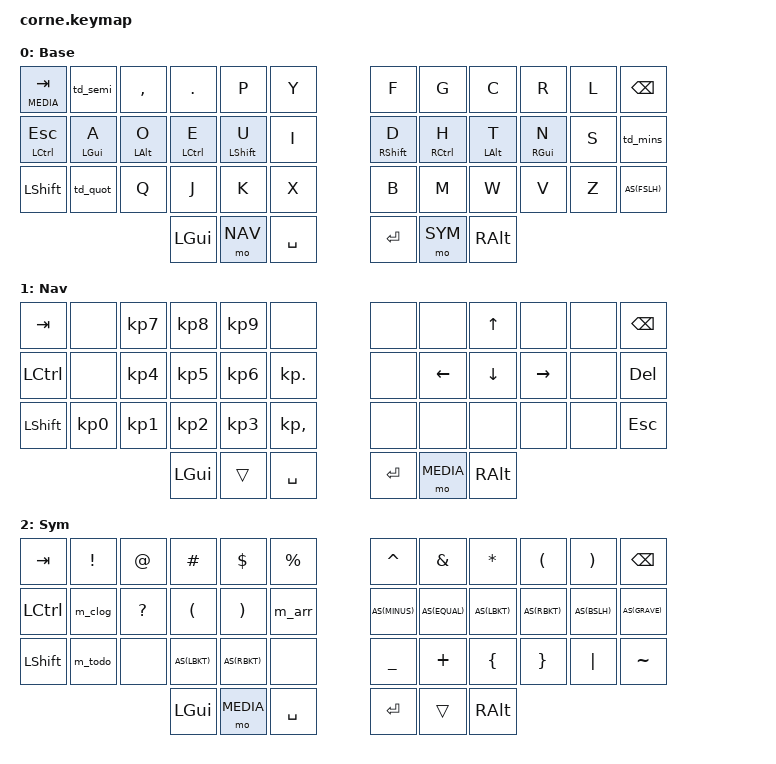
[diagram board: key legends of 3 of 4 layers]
// Port a ZMK de current/qmk/keymap.c. Mantener ambos sincronizados.

#include <behaviors.dtsi>
#include <dt-bindings/zmk/keys.h>
#include <dt-bindings/zmk/bt.h>
#include <dt-bindings/zmk/outputs.h>

#define BASE  0
#define NAV   1
#define SYM   2
#define MEDIA 3

// Auto Shift (QMK AUTO_SHIFT + NO_AUTO_SHIFT_ALPHA): tap = tecla, mantener
// 200 ms = tecla con Shift. Pulsar otra tecla antes resuelve como tap.
// Solo en números y símbolos sin Shift.
#define AS(k) &ashift LS(k) k

// ── Hold-tap global (equivale a TAPPING_TERM 220 + TAPPING_FORCE_HOLD, sin
// PERMISSIVE_HOLD): decide solo por tiempo, sin auto-repeat tras un tap ─────
&mt {
    flavor = "tap-preferred";
    tapping-term-ms = <220>;
    quick-tap-ms = <0>;
};

&lt {
    tapping-term-ms = <220>;
    quick-tap-ms = <0>;
};

/ {
    behaviors {
        ashift: auto_shift {
            compatible = "zmk,behavior-hold-tap";
            #binding-cells = <2>;
            flavor = "tap-unless-interrupted";
            tapping-term-ms = <200>;
            quick-tap-ms = <0>;
            bindings = <&kp>, <&kp>;
        };

        // ── Tap Dance ────────────────────────────────────────────────────
        td_semi: td_semi {
            compatible = "zmk,behavior-tap-dance";
            #binding-cells = <0>;
            tapping-term-ms = <220>;
            bindings = <&kp SEMI>, <&kp COLON>;
        };
        td_quot: td_quot {
            compatible = "zmk,behavior-tap-dance";
            #binding-cells = <0>;
            tapping-term-ms = <220>;
            bindings = <&kp SQT>, <&kp DQT>;
        };
        td_mins: td_mins {
            compatible = "zmk,behavior-tap-dance";
            #binding-cells = <0>;
            tapping-term-ms = <220>;
            bindings = <&kp MINUS>, <&kp UNDER>;
        };
    };

    // ── Macros ───────────────────────────────────────────────────────────
    macros {
        m_clog: m_clog {
            compatible = "zmk,behavior-macro";
            #binding-cells = <0>;
            bindings = <&macro_tap &kp C &kp O &kp N &kp S &kp O &kp L &kp E
                        &kp DOT &kp L &kp O &kp G &kp LPAR &kp RPAR>;
        };
        m_arr: m_arr {
            compatible = "zmk,behavior-macro";
            #binding-cells = <0>;
            bindings = <&macro_tap &kp LPAR &kp RPAR &kp SPACE &kp EQUAL &kp GT
                        &kp SPACE &kp LBRC &kp RBRC>;
        };
        m_todo: m_todo {
            compatible = "zmk,behavior-macro";
            #binding-cells = <0>;
            bindings = <&macro_tap &kp FSLH &kp FSLH &kp SPACE &kp T &kp O &kp D
                        &kp O &kp COLON &kp SPACE>;
        };
    };

    // ── Combos (posiciones: 0-11 fila 1, 12-23 fila 2, 24-35 fila 3,
    // 36-41 pulgares) ────────────────────────────────────────────────────
    combos {
        compatible = "zmk,combos";
        combo_esc {
            timeout-ms = <50>;
            key-positions = <27 28>;  // J + K
            bindings = <&kp ESC>;
            layers = <BASE>;
        };
        combo_paren_open {
            timeout-ms = <50>;
            key-positions = <6 7>;    // F + G
            bindings = <&kp LPAR>;
            layers = <BASE>;
        };
        combo_paren_close {
            timeout-ms = <50>;
            key-positions = <7 8>;    // G + C
            bindings = <&kp RPAR>;
            layers = <BASE>;
        };
        combo_brack_open {
            timeout-ms = <50>;
            key-positions = <30 31>;  // B + M
            bindings = <&kp LBKT>;
            layers = <BASE>;
        };
        combo_brack_close {
            timeout-ms = <50>;
            key-positions = <31 32>;  // M + W
            bindings = <&kp RBKT>;
            layers = <BASE>;
        };
    };

    keymap {
        compatible = "zmk,keymap";

        base_layer {
            display-name = "Base";
            bindings = <
   &lt MEDIA TAB  &td_semi       &kp COMMA      &kp DOT          &kp P            &kp Y          &kp F            &kp G            &kp C           &kp R            &kp L  &kp BSPC
   &mt LCTRL ESC  &mt LGUI A     &mt LALT O     &mt LCTRL E      &mt LSHFT U      &kp I          &mt RSHFT D      &mt RCTRL H      &mt LALT T      &mt RGUI N       &kp S  &td_mins
   &kp LSHFT      &td_quot       &kp Q          &kp J            &kp K            &kp X          &kp B            &kp M            &kp W           &kp V            &kp Z  AS(FSLH)
                                                &kp LGUI         &mo NAV          &kp SPACE      &kp RET          &mo SYM          &kp RALT
            >;
        };

        nav_layer {
            display-name = "Nav";
            bindings = <
   &kp TAB    &none      &kp KP_N7  &kp KP_N8  &kp KP_N9  &none          &none      &none      &kp UP     &none      &none  &kp BSPC
   &kp LCTRL  &none      &kp KP_N4  &kp KP_N5  &kp KP_N6  &kp KP_DOT     &none      &kp LEFT   &kp DOWN   &kp RIGHT  &none  &kp DEL
   &kp LSHFT  &kp KP_N0  &kp KP_N1  &kp KP_N2  &kp KP_N3  &kp KP_COMMA   &none      &none      &none      &none      &none  &kp ESC
                                    &kp LGUI   &trans     &kp SPACE      &kp RET    &mo MEDIA  &kp RALT
            >;
        };

        sym_layer {
            display-name = "Sym";
            bindings = <
   &kp TAB    &kp EXCL   &kp AT     &kp HASH   &kp DLLR   &kp PRCNT      &kp CARET  &kp AMPS   &kp STAR   &kp LPAR   &kp RPAR   &kp BSPC
   &kp LCTRL  &m_clog    &kp QMARK  &kp LPAR   &kp RPAR   &m_arr         AS(MINUS)  AS(EQUAL)  AS(LBKT)   AS(RBKT)   AS(BSLH)   AS(GRAVE)
   &kp LSHFT  &m_todo    &none      AS(LBKT)   AS(RBKT)   &none          &kp UNDER  &kp PLUS   &kp LBRC   &kp RBRC   &kp PIPE   &kp TILDE
                                    &kp LGUI   &mo MEDIA  &kp SPACE      &kp RET    &trans     &kp RALT
            >;
        };

        // Fila inferior izquierda: Bluetooth (no existe en la versión QMK).
        // BT_SEL n = perfil/equipo n, BT_CLR = olvida el perfil activo,
        // OUT_USB / OUT_BLE = enviar por cable o por Bluetooth.
        media_layer {
            display-name = "Media";
            bindings = <
   &none         &none         &kp C_PREV    &kp C_PP              &kp C_NEXT        &kp C_VOL_UP   &kp KP_PLUS      AS(N7)  AS(N8)  AS(N9)  &kp KP_MINUS   &kp BSPC
   &none         &none         &none         &kp LC(LS(LG(N4)))    &kp LS(LG(N4))    &kp C_VOL_DN   &kp KP_MULTIPLY  AS(N4)  AS(N5)  AS(N6)  &kp KP_DIVIDE  &none
   &bt BT_SEL 0  &bt BT_SEL 1  &bt BT_SEL 2  &bt BT_CLR            &out OUT_USB      &out OUT_BLE   AS(N0)           AS(N1)  AS(N2)  AS(N3)  AS(COMMA)      &none
                                             &kp LGUI              &trans            &kp SPACE      &kp RET          &trans  &kp RALT
            >;
        };
    };
};
